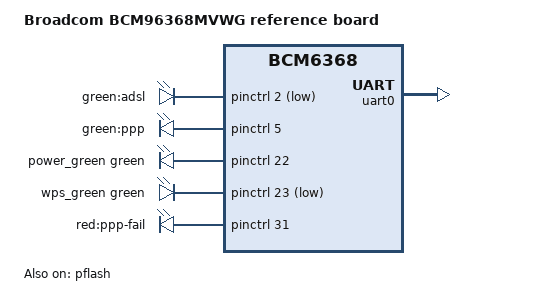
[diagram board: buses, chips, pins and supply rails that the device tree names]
#include "bcm6368.dtsi"

#include <dt-bindings/input/input.h>
#include <dt-bindings/leds/common.h>

/ {
	model = "Broadcom BCM96368MVWG reference board";
	compatible = "brcm,bcm96368mvwg", "brcm,bcm6368";

	chosen {
		bootargs = "rootfstype=squashfs,jffs2 noinitrd console=ttyS0,115200";
		stdout-path = "serial0:115200n8";
	};

	leds {
		compatible = "gpio-leds";

		dsl_green {
			label = "green:adsl";
			gpios = <&pinctrl 2 1>;
		};
		ppp_green {
			label = "green:ppp";
			gpios = <&pinctrl 5 0>;
		};
		power_green {
			function = LED_FUNCTION_POWER;
			color = <LED_COLOR_ID_GREEN>;
			gpios = <&pinctrl 22 0>;
			default-state = "on";
		};
		wps_green {
			function = LED_FUNCTION_WPS;
			color = <LED_COLOR_ID_GREEN>;
			gpios = <&pinctrl 23 1>;
		};
		ppp_fail_red {
			label = "red:ppp-fail";
			gpios = <&pinctrl 31 0>;
		};
	};
};

&pflash {
	status = "okay";

	partitions {
		compatible = "brcm,bcm963xx-cfe-nor-partitions";
	};
};

&pinctrl {
	pinctrl-names = "default";
	pinctrl-0 = <&pinctrl_pci>;
};

&uart0 {
	status = "okay";
};
